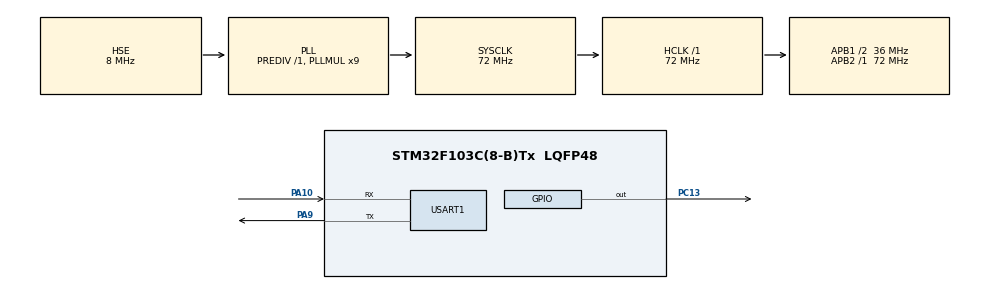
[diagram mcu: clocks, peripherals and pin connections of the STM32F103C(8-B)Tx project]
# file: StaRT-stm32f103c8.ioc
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Mcu.Family=STM32F1
Mcu.Name=STM32F103C(8-B)Tx
Mcu.Package=LQFP48
NVIC.PriorityGroup=NVIC_PRIORITYGROUP_4
PA10.Mode=Asynchronous
PA10.Signal=USART1_RX
PA13.Mode=Serial_Wire
PA13.Signal=SYS_JTMS-SWDIO
PA14.Mode=Serial_Wire
PA14.Signal=SYS_JTCK-SWCLK
PA9.Mode=Asynchronous
PA9.Signal=USART1_TX
PC13-TAMPER-RTC.GPIO_Speed=GPIO_SPEED_FREQ_LOW
PC13-TAMPER-RTC.Signal=GPIO_Output
PC14-OSC32_IN.Mode=LSE-External-Oscillator
PC14-OSC32_IN.Signal=RCC_OSC32_IN
PC15-OSC32_OUT.Mode=LSE-External-Oscillator
PC15-OSC32_OUT.Signal=RCC_OSC32_OUT
PD0-OSC_IN.Mode=HSE-External-Oscillator
PD0-OSC_IN.Signal=RCC_OSC_IN
PD1-OSC_OUT.Mode=HSE-External-Oscillator
PD1-OSC_OUT.Signal=RCC_OSC_OUT
ProjectManager.HeapSize=0x200
ProjectManager.StackSize=0x400
ProjectManager.TargetToolchain=MDK-ARM V5.32
RCC.AHBFreq_Value=72000000
RCC.APB1CLKDivider=RCC_HCLK_DIV2
RCC.APB1Freq_Value=36000000
RCC.APB1TimFreq_Value=72000000
RCC.APB2Freq_Value=72000000
RCC.APB2TimFreq_Value=72000000
RCC.HCLKFreq_Value=72000000
RCC.PLLMUL=RCC_PLL_MUL9
RCC.PLLSourceVirtual=RCC_PLLSOURCE_HSE
RCC.SYSCLKFreq_VALUE=72000000
RCC.SYSCLKSource=RCC_SYSCLKSOURCE_PLLCLK
RCC.USBFreq_Value=72000000
USART1.VirtualMode=VM_ASYNC
board=custom

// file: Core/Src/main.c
/* USER CODE BEGIN Header */
/**
  ******************************************************************************
  * @file           : main.c
  * @brief          : Main program body
  ******************************************************************************
  * @attention
  *
  * Copyright (c) 2025 STMicroelectronics.
  * All rights reserved.
  *
  * This software is licensed under terms that can be found in the LICENSE file
  * in the root directory of this software component.
  * If no LICENSE file comes with this software, it is provided AS-IS.
  *
  ******************************************************************************
  */
/* USER CODE END Header */
#include "main.h"

/* USER CODE BEGIN PD */
#define THREAD_STACK_SIZE 512

#define MSG_QUEUE_SIZE 10
#define MSG_POOL_SIZE  START_MSGQ_POOL_SIZE(sizeof(msg_t),MSG_QUEUE_SIZE) // 10条消息，每条4字节
/* USER CODE END PD */

UART_HandleTypeDef huart1;

void SystemClock_Config(void);
static void MX_GPIO_Init(void);
static void MX_USART1_UART_Init(void);

/* USER CODE BEGIN 0 */
s_mutex mutex1;

s_thread thread1;
s_thread thread2;
s_thread thread3;
s_uint8_t i,j = 0,k = 10;

s_uint8_t thread1stack[THREAD_STACK_SIZE];
s_uint8_t thread2stack[THREAD_STACK_SIZE];
s_uint8_t thread3stack[THREAD_STACK_SIZE];

void thread1entry(void);
void thread2entry(void);
void thread3entry(void);

void s_putc(char c)
{
    // 通过串口发送字符
    HAL_UART_Transmit(&huart1, (uint8_t *)&c, 1, HAL_MAX_DELAY);
}
#if START_USING_UDELAY
/* DWT (Data Watchpoint and Trace) 寄存器地址 */
#define DWT_CR      *(volatile uint32_t *)0xE0001000
#define DWT_CYCCNT  *(volatile uint32_t *)0xE0001004
#define DEM_CR      *(volatile uint32_t *)0xE000EDFC
#define DEM_CR_TRCENA       (1 << 24)
#define DWT_CR_CYCCNTENA    (1 << 0)

void DWT_Init(void)
{
    /* 使能 DWT 外设 */
    DEM_CR |= DEM_CR_TRCENA;
    /* DWT CYCCNT 寄存器清零 */
    DWT_CYCCNT = 0;
    /* 使能 Cortex-M DWT CYCCNT 寄存器 */
    DWT_CR |= DWT_CR_CYCCNTENA;
}

void DWT_Delay_us(s_uint32_t us)
{
    uint32_t start = DWT_CYCCNT;
    uint32_t ticks = us * (SystemCoreClock / 1000000);
    while ((DWT_CYCCNT - start) < ticks);
}
#endif /* START_USING_UDELAY */
/* USER CODE END 0 */

int main(void)
{

  /* MCU Configuration--------------------------------------------------------*/

  /* Reset of all peripherals, Initializes the Flash interface and the Systick. */
  HAL_Init();

  /* Configure the system clock */
  SystemClock_Config();

  /* Initialize all configured peripherals */
  MX_GPIO_Init();
  MX_USART1_UART_Init();
  /* USER CODE BEGIN 2 */
	s_start_init();
#if START_USING_UDELAY
  DWT_Init();
  s_udelay_set_hook(DWT_Delay_us);
#endif

  s_mutex_init(&mutex1,START_IPC_FLAG_FIFO);

	s_thread_init(&thread1,
						thread1entry,
						thread1stack,
						THREAD_STACK_SIZE,
						10,
						10);
	s_thread_startup(&thread1);
	s_thread_init(&thread2,
						thread2entry,
						thread2stack,
						THREAD_STACK_SIZE,
					  12,
						10);
	s_thread_startup(&thread2);
  s_thread_init(&thread3,
            thread3entry,
            thread3stack,
            THREAD_STACK_SIZE,
            15,
            10);
  s_thread_startup(&thread3);

	s_sched_start();
  /* USER CODE END 2 */

  /* Infinite loop */
 while (1)
 {

 }
}

void SystemClock_Config(void)
{
  RCC_OscInitTypeDef RCC_OscInitStruct = {0};
  RCC_ClkInitTypeDef RCC_ClkInitStruct = {0};

  /** Initializes the RCC Oscillators according to the specified parameters
  * in the RCC_OscInitTypeDef structure.
  */
  RCC_OscInitStruct.OscillatorType = RCC_OSCILLATORTYPE_HSE;
  RCC_OscInitStruct.HSEState = RCC_HSE_ON;
  RCC_OscInitStruct.HSEPredivValue = RCC_HSE_PREDIV_DIV1;
  RCC_OscInitStruct.HSIState = RCC_HSI_ON;
  RCC_OscInitStruct.PLL.PLLState = RCC_PLL_ON;
  RCC_OscInitStruct.PLL.PLLSource = RCC_PLLSOURCE_HSE;
  RCC_OscInitStruct.PLL.PLLMUL = RCC_PLL_MUL9;
  if (HAL_RCC_OscConfig(&RCC_OscInitStruct) != HAL_OK)
  {
    Error_Handler();
  }

  /** Initializes the CPU, AHB and APB buses clocks
  */
  RCC_ClkInitStruct.ClockType = RCC_CLOCKTYPE_HCLK|RCC_CLOCKTYPE_SYSCLK
                              |RCC_CLOCKTYPE_PCLK1|RCC_CLOCKTYPE_PCLK2;
  RCC_ClkInitStruct.SYSCLKSource = RCC_SYSCLKSOURCE_PLLCLK;
  RCC_ClkInitStruct.AHBCLKDivider = RCC_SYSCLK_DIV1;
  RCC_ClkInitStruct.APB1CLKDivider = RCC_HCLK_DIV2;
  RCC_ClkInitStruct.APB2CLKDivider = RCC_HCLK_DIV1;

  if (HAL_RCC_ClockConfig(&RCC_ClkInitStruct, FLASH_LATENCY_2) != HAL_OK)
  {
    Error_Handler();
  }
}

static void MX_USART1_UART_Init(void)
{

  huart1.Instance = USART1;
  huart1.Init.BaudRate = 115200;
  huart1.Init.WordLength = UART_WORDLENGTH_8B;
  huart1.Init.StopBits = UART_STOPBITS_1;
  huart1.Init.Parity = UART_PARITY_NONE;
  huart1.Init.Mode = UART_MODE_TX_RX;
  huart1.Init.HwFlowCtl = UART_HWCONTROL_NONE;
  huart1.Init.OverSampling = UART_OVERSAMPLING_16;
  if (HAL_UART_Init(&huart1) != HAL_OK)
  {
    Error_Handler();
  }

}

static void MX_GPIO_Init(void)
{
  GPIO_InitTypeDef GPIO_InitStruct = {0};

  /* GPIO Ports Clock Enable */
  __HAL_RCC_GPIOC_CLK_ENABLE();
  __HAL_RCC_GPIOD_CLK_ENABLE();
  __HAL_RCC_GPIOA_CLK_ENABLE();

  /*Configure GPIO pin Output Level */
  HAL_GPIO_WritePin(GPIOC, GPIO_PIN_13, GPIO_PIN_RESET);

  /*Configure GPIO pin : PC13 */
  GPIO_InitStruct.Pin = GPIO_PIN_13;
  GPIO_InitStruct.Mode = GPIO_MODE_OUTPUT_PP;
  GPIO_InitStruct.Pull = GPIO_NOPULL;
  GPIO_InitStruct.Speed = GPIO_SPEED_FREQ_LOW;
  HAL_GPIO_Init(GPIOC, &GPIO_InitStruct);

}

/* USER CODE BEGIN 4 */
void thread1entry() /* High priority (等待互斥量) */
{
    static int phase = 0;
    while (1)
    {
        if (phase == 0)
        {
            s_mdelay(100); /* 先让低优先级线程获取互斥量制造反转 */
            s_printf("HIGH : try take mutex\n");
            if (S_OK == s_mutex_take(&mutex1, START_WAITING_FOREVER))
            {
                s_printf("HIGH : got mutex (after inheritance) j=%d\n", j);
                s_mutex_release(&mutex1);
                s_printf("HIGH : released mutex\n");
                phase = 1;
            }
        }
        else
        {
            /* 后续简单演示重复获取/释放 */
            if (S_OK == s_mutex_take(&mutex1, START_WAITING_FOREVER))
            {
                s_mutex_release(&mutex1);
            }
            s_mdelay(600);
        }
        j++;
        if (j == 255) j = 0;
        s_mdelay(50);
    }
}

void thread2entry() /* Medium priority (制造 CPU 干扰) */
{
    while (1)
    {
        i++;
        if (i % 50 == 0)
            s_printf("MED  : running i=%d\n", i);
        if (i == 255) i = 0;
        /* 不使用互斥量，纯粹占用时间片 */
        s_mdelay(40);
    }
}

void thread3entry() /* Low priority (先获取互斥量并长时间占用) */
{
    static int once = 0;
    s_uint8_t base_prio_saved = 0;
    while (1)
    {
        if (once == 0)
        {
            if (S_OK == s_mutex_take(&mutex1, START_WAITING_FOREVER))
            {
                base_prio_saved = s_thread_get()->current_priority;
                s_printf("LOW  : took mutex, do long work (base prio=%d)\n",
                         base_prio_saved);

                /* 模拟长任务分多段，期间高优先级会等待，触发优先级继承 */
                for (int seg = 0; seg < 5; seg++)
                {
                    s_mdelay(120); /* 每段持有 */
                    s_thread *self = s_thread_get();
                    if (self)
                    {
                        if (self->current_priority != base_prio_saved)
                            s_printf("LOW  : inherited priority -> %d (seg=%d)\n",
                                     self->current_priority, seg);
                    }
                }

                s_printf("LOW  : releasing mutex\n");
                s_mutex_release(&mutex1);
                s_printf("LOW  : released mutex (should drop back to prio=%d)\n",
                         base_prio_saved);
                once = 1;
            }
        }
        else
        {
            /* 之后偶尔再占用一下，验证递归外正常路径 */
            if (S_OK == s_mutex_take(&mutex1, START_WAITING_FOREVER))
            {
                s_mdelay(30);
                s_mutex_release(&mutex1);
            }
            s_mdelay(200);
        }

        k++;
        if (k == 255) k = 0;
        s_mdelay(10);
    }
}
/* USER CODE END 4 */

void Error_Handler(void)
{
  __disable_irq();
  while (1)
  {
  }
}
